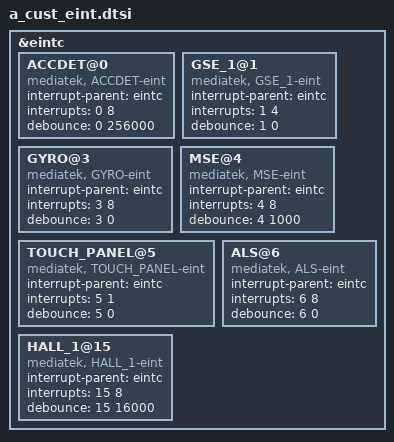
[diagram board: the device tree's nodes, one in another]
/*
 * Generated by MTK SP DrvGen Version 03.13.6 for MT6580. Copyright MediaTek Inc. (C) 2013.
 * Sun Feb 26 17:38:27 2017
 * Do Not Modify the File.
 */

/*************************
 * EINT DTSI File
*************************/

&eintc {
	ACCDET@0 {
		compatible = "mediatek, ACCDET-eint";
		interrupt-parent = <&eintc>;
		interrupts = <0 8>;
		debounce = <0 256000>;
	};

	GSE_1@1 {
		compatible = "mediatek, GSE_1-eint";
		interrupt-parent = <&eintc>;
		interrupts = <1 4>;
		debounce = <1 0>;
	};

	GYRO@3 {
		compatible = "mediatek, GYRO-eint";
		interrupt-parent = <&eintc>;
		interrupts = <3 8>;
		debounce = <3 0>;
	};

	MSE@4 {
		compatible = "mediatek, MSE-eint";
		interrupt-parent = <&eintc>;
		interrupts = <4 8>;
		debounce = <4 1000>;
	};

	TOUCH_PANEL@5 {
		compatible = "mediatek, TOUCH_PANEL-eint";
		interrupt-parent = <&eintc>;
		interrupts = <5 1>;
		debounce = <5 0>;
	};

	ALS@6 {
		compatible = "mediatek, ALS-eint";
		interrupt-parent = <&eintc>;
		interrupts = <6 8>;
		debounce = <6 0>;
	};

	HALL_1@15 {
		compatible = "mediatek, HALL_1-eint";
		interrupt-parent = <&eintc>;
		interrupts = <15 8>;
		debounce = <15 16000>;
	};

};
